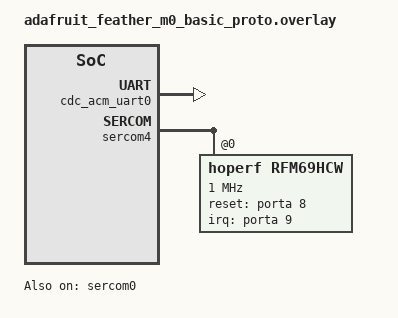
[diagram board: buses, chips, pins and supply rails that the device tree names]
/*
 * Adafruit Feather M0 + RFM69HCW overlay
 *
 * Pinout matches the Adafruit Feather M0 RFM69HCW Packet Radio (and the
 * Feather M0 LoRa radio pinout):
 *   CS  = D8  = PA06
 *   RST = D4  = PA08
 *   IRQ = D3  = PA09 (RFM69 DIO0)
 *   SPI = Feather hardware SPI on SERCOM4 (MISO/MOSI/SCK)
 *
 * Board target: adafruit_feather_m0_basic_proto
 */

&zephyr_udc0 {
	cdc_acm_uart0: cdc_acm_uart0 {
		compatible = "zephyr,cdc-acm-uart";
		rx-fifo-size = <512>;
		tx-fifo-size = <512>;
	};
};

&sercom4 {
	status = "okay";
	cs-gpios = <&porta 6 GPIO_ACTIVE_LOW>;

	rfm69: rfm69@0 {
		compatible = "hoperf,rfm69hcw";
		reg = <0>;
		/* Conservative clock for initial ground-station hardware validation. */
		spi-max-frequency = <1000000>;
		reset-gpios = <&porta 8 GPIO_ACTIVE_HIGH>;
		irq-gpios = <&porta 9 (GPIO_PULL_DOWN | GPIO_ACTIVE_HIGH)>;
		label = "RFM69HCW";
	};
};

/* SERCOM0 UART on D0/RX (PA11) and D1/TX (PA10): text event console to FTDI. */
&sercom0 {
	status = "okay";
};

/ {
	chosen {
		zephyr,console = &sercom0;
		zephyr,shell-uart = &sercom0;
	};

	aliases {
		rfm69 = &rfm69;
		/* SPI controller used by the radio (for ZephyrSpiDriver) */
		spi-rfm69 = &sercom4;
	};
};
